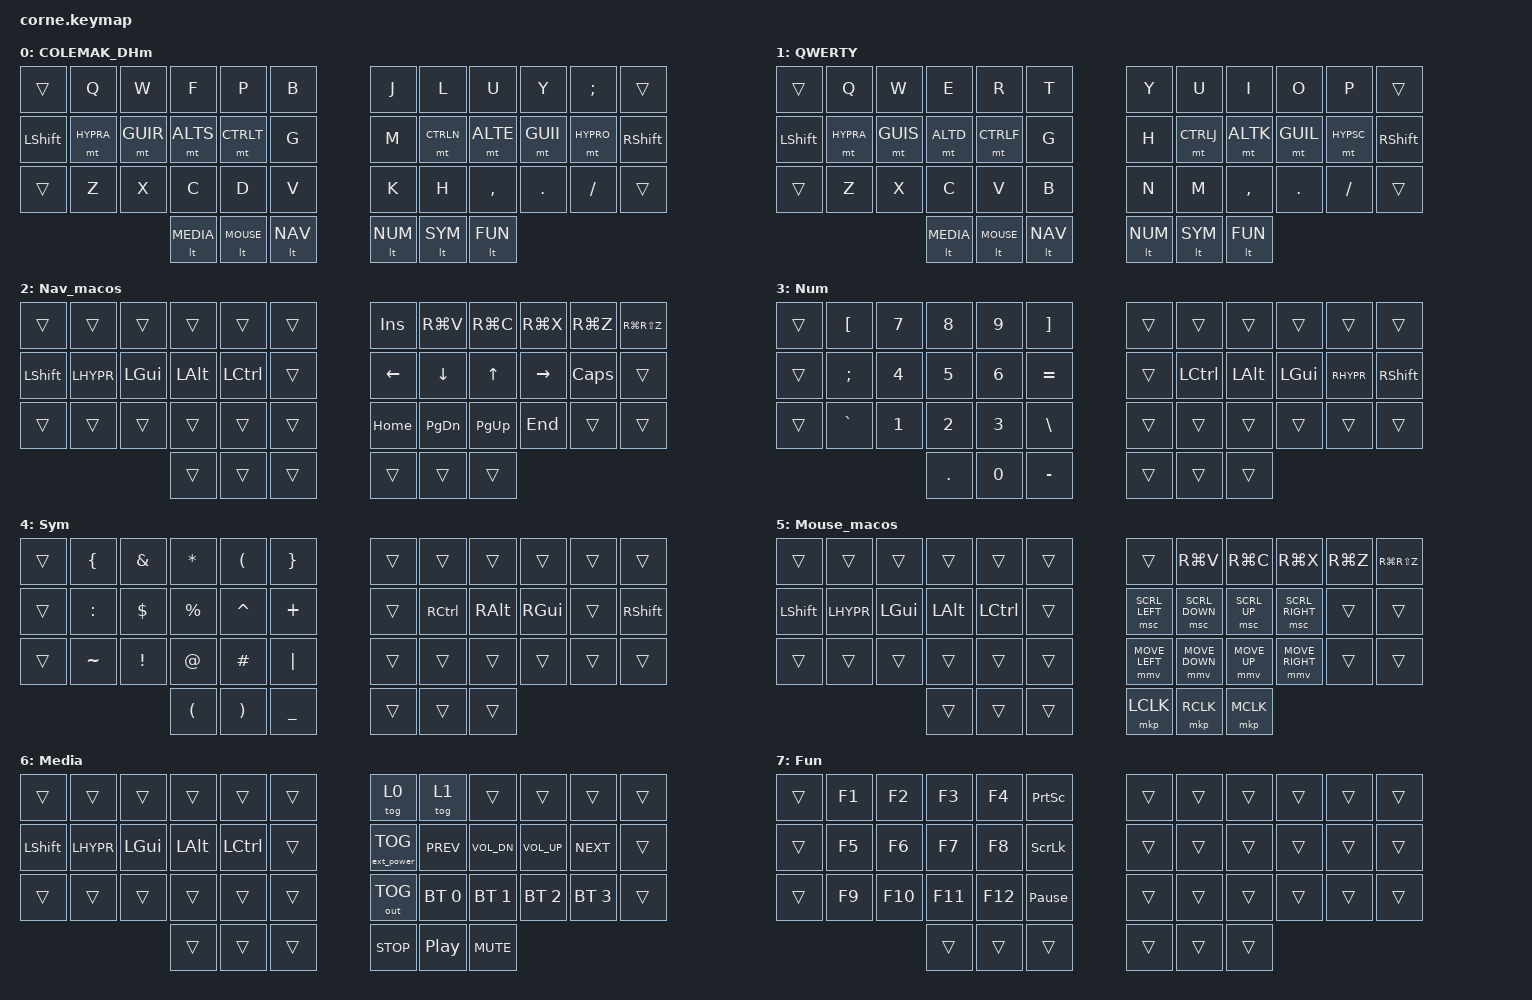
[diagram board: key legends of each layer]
#include <behaviors.dtsi>
#include <dt-bindings/zmk/bt.h>
#include <dt-bindings/zmk/ext_power.h>
#include <dt-bindings/zmk/keys.h>
#include <dt-bindings/zmk/outputs.h>
#include <dt-bindings/zmk/pointing.h>

#define HYPRA LA(LG(LEFT_CONTROL)) A
#define GUIR LEFT_GUI R
#define ALTS LEFT_ALT S
#define CTRLT LEFT_CONTROL T
#define CTRLN RIGHT_CONTROL N
#define ALTE RIGHT_ALT E
#define GUII RIGHT_GUI I
#define HYPRO RA(RG(RIGHT_CONTROL)) O
#define MEDIA 6 DEL
#define MOUSE 5 ENTER
#define NAV 2 BACKSPACE
#define NUM 3 SPACE
#define SYM 4 TAB
#define FUN 7 ESC
#define GUIS LEFT_GUI S
#define ALTD LEFT_ALT D
#define CTRLF LEFT_CONTROL F
#define CTRLJ RIGHT_CONTROL J
#define ALTK RIGHT_ALT K
#define GUIL RIGHT_GUI L
#define HYPSC RA(RG(RIGHT_CONTROL)) SEMICOLON
#define LHYPR LA(LG(LEFT_CONTROL))
#define RHYPR RA(RG(RCTRL))

/ {
    keymap {
        compatible = "zmk,keymap";

        COLEMAK_DHm {
                        bindings = <
&trans    &kp Q     &kp W    &kp F     &kp P     &kp B   &kp J   &kp L     &kp U     &kp Y    &kp SEMICOLON &trans
&kp LSHFT &mt HYPRA &mt GUIR &mt ALTS  &mt CTRLT &kp G   &kp M   &mt CTRLN &mt ALTE  &mt GUII &mt HYPRO     &kp RSHIFT
&trans    &kp Z     &kp X    &kp C     &kp D     &kp V   &kp K   &kp H     &kp COMMA &kp DOT  &kp FSLH      &trans
                             &lt MEDIA &lt MOUSE &lt NAV &lt NUM &lt SYM   &lt FUN
            >;
        };

        QWERTY {
                        bindings = <
&trans     &kp Q      &kp W    &kp E     &kp R     &kp T   &kp Y    &kp U     &kp I     &kp O    &kp P     &trans
&kp LSHFT  &mt HYPRA  &mt GUIS &mt ALTD  &mt CTRLF &kp G   &kp H    &mt CTRLJ &mt ALTK  &mt GUIL &mt HYPSC &kp RSHIFT
&trans     &kp Z      &kp X    &kp C     &kp V     &kp B   &kp N    &kp M     &kp COMMA &kp DOT  &kp FSLH  &trans
                               &lt MEDIA &lt MOUSE &lt NAV &lt NUM  &lt SYM   &lt FUN
            >;
        };

        Nav_macos {
                        bindings = <
&trans     &trans    &trans   &trans   &trans    &trans &kp INSERT &kp RG(V) &kp RG(C) &kp RG(X) &kp RG(Z) &kp RG(RS(Z))
&kp LSHIFT &kp LHYPR &kp LGUI &kp LALT &kp LCTRL &trans &kp LEFT   &kp DOWN  &kp UP    &kp RIGHT &kp CAPS  &trans
&trans     &trans    &trans   &trans   &trans    &trans &kp HOME   &kp PG_DN &kp PG_UP &kp END   &trans    &trans
                             &trans   &trans    &trans &trans     &trans    &trans
            >;
        };

        Num {
            bindings = <
&trans &kp LBKT  &kp N7 &kp N8  &kp N9 &kp RBKT  &trans &trans    &trans   &trans   &trans    &trans
&trans &kp SEMI  &kp N4 &kp N5  &kp N6 &kp EQUAL &trans &kp LCTRL &kp LALT &kp LGUI &kp RHYPR &kp RSHFT
&trans &kp GRAVE &kp N1 &kp N2  &kp N3 &kp BSLH  &trans &trans    &trans   &trans   &trans    &trans
                        &kp DOT &kp N0 &kp MINUS &trans &trans    &trans
            >;
        };

        Sym {
            bindings = <
&trans &kp LBRC  &kp AMPS &kp STAR  &kp LPAR  &kp RBRC  &trans &trans    &trans   &trans   &trans &trans
&trans &kp COLON &kp DLLR &kp PRCNT &kp CARET &kp PLUS  &trans &kp RCTRL &kp RALT &kp RGUI &trans &kp RSHFT
&trans &kp TILDE &kp EXCL &kp AT    &kp HASH  &kp PIPE  &trans &trans    &trans   &trans   &trans &trans
                          &kp LPAR  &kp RPAR  &kp UNDER &trans &trans    &trans
            >;
        };

        Mouse_macos {
            bindings = <
&trans     &trans    &trans   &trans   &trans     &trans    &trans          &kp RG(V)       &kp RG(C)     &kp RG(X)        &kp RG(Z)  &kp RG(RS(Z))
&kp LSHIFT &kp LHYPR &kp LGUI &kp LALT &kp LCTRL  &trans    &msc SCRL_LEFT  &msc SCRL_DOWN  &msc SCRL_UP  &msc SCRL_RIGHT  &trans     &trans
&trans     &trans    &trans   &trans   &trans     &trans    &mmv MOVE_LEFT  &mmv MOVE_DOWN  &mmv MOVE_UP  &mmv MOVE_RIGHT  &trans     &trans
                              &trans   &trans     &trans    &mkp LCLK       &mkp RCLK       &mkp MCLK
            >;
        };

        Media {
            bindings = <
&trans     &trans    &trans   &trans   &trans    &trans &tog 0             &tog 1            &trans        &trans        &trans        &trans
&kp LSHIFT &kp LHYPR &kp LGUI &kp LALT &kp LCTRL &trans &ext_power EP_TOG  &kp C_PREV        &kp C_VOL_DN  &kp C_VOL_UP  &kp C_NEXT    &trans
&trans     &trans    &trans   &trans   &trans    &trans &out OUT_TOG       &bt BT_SEL 0      &bt BT_SEL 1  &bt BT_SEL 2  &bt BT_SEL 3  &trans
                              &trans   &trans    &trans &kp C_STOP         &kp C_PLAY_PAUSE  &kp C_MUTE
            >;
        };

        Fun {
            bindings = <
&trans &kp F1 &kp F2  &kp F3  &kp F4  &kp PRINTSCREEN &trans &trans &trans &trans &trans &trans
&trans &kp F5 &kp F6  &kp F7  &kp F8  &kp SCROLLLOCK  &trans &trans &trans &trans &trans &trans
&trans &kp F9 &kp F10 &kp F11 &kp F12 &kp PAUSE_BREAK &trans &trans &trans &trans &trans &trans
                      &trans  &trans  &trans          &trans &trans &trans
            >;
        };
    };
};

